# RTS5918 register map
Vendor: Realtek Semiconductor Corp.; Series: RTS5918 Series; File version: 1.00
CPU: ARMV8MML r0p0, little endian, MPU, FPU, VTOR, 3 interrupt priority bits, 8 SAU regions
Registers are 32-bit, read-write, reset 0x0 unless marked. A register's access mark holds for its fields unless they carry their own. Offsets are from the block's base; [hi:lo] are bit positions; {n}, {i} and the like mark numbered series; 'fields as' and 'values as' point back to an identical list.

## I3C0 — I3C Controller
Base 0x40003000
Same registers: I3C1 0x40004000
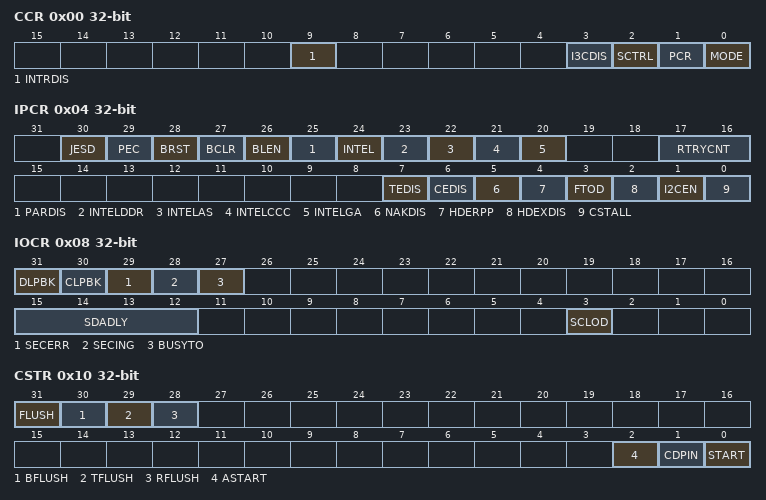
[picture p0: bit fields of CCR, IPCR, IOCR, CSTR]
0x00 CCR — CONFIGURATION CONTROL REGISTER
  [9] INTRDIS — Interrupt Disable
    0=ENABLE (Enable interrupt); 1=DISABLE (Disable interrupt)
  [3] I3CDIS — I3C Disable
    0=ENABLE (Enable I3C); 1=DISABLE (Disable I3C)
  [2] SCTRL — Secondary Control Mode
    0=DISABLE (Disable secondary control mode); 1=ENABLE (Enable secondary control mode)
  [1] PCR — Primary Control
    0=DISABLE (Not Primary Control); 1=ENABLE (Primary Control)
  [0] MODE — Mode Select
    0=CONTROLLER (I3C Controller); 1=TARGET (I3C Target)
0x04 IPCR — IXC PROTOCOL CONTROL REGISTER
  [30] JESD — JESD Spec. Enable
    0=DISABLE (Disable JESD); 1=ENABLE (Enable JESD)
  [29] PEC — PEC CRC Enable
    0=DISABLE (Disable PEC CRC); 1=ENABLE (Enable PEC CRC)
  [28] BRST — Bus Reset Enable
    0=DISABLE (Disable bus reset); 1=ENABLE (Enable bus reset)
  [27] BCLR — Bus Clear Enable
    0=DISABLE (Disable bus clear); 1=ENABLE (Enable bus clear)
  [26] BLEN — BL Enable
    0=DISABLE (Disable BL); 1=ENABLE (Enable BL)
  [25] PARDIS — Parity Disable
    0=ENABLE (Enable Parity); 1=DISABLE (Disable Parity)
  [24] INTEL — INTEL Spec. Enable
    0=DISABLE (Disable Intel spec.); 1=ENABLE (Enable Intel spec.)
  [23] INTELDDR — INTEL Spec. Extend DDR Enable
    0=DISABLE (Disable Intel Spec. extend DDR); 1=ENABLE (Enable Intel Spec. extend DDR)
  [22] INTELAS — INTEL Spec. Extend AS Enable
    0=DISABLE (Disable Intel Spec. extend AS); 1=ENABLE (Enable Intel Spec. extend AS)
  [21] INTELCCC — INTEL Spec. Extend CCC Enable
    0=DISABLE (Disable Intel Spec. extend CCC); 1=ENABLE (Enable Intel Spec. extend CCC)
  [20] INTELGA — INTEL Spec. Extend GA Enable
    0=DISABLE (Disable Intel Spec. extend GA); 1=ENABLE (Enable Intel Spec. extend GA)
  [17:16] RTRYCNT — Read Retry Count
  [7] TEDIS — TAGT Error Disable
    0=ENABLE (Enable target mode error); 1=DISABLE (Disable target mode error)
  [6] CEDIS — CTRL Error Disable
    0=ENABLE (Enable control mode error); 1=DISABLE (Disable control mode error)
  [5] NAKDIS — RX NACK Disable
    0=ENABLE (Enable RX NACK); 1=DISABLE (Disable RX NACK)
  [4] HDERPP — Header Address turn to PP Timing Enable
    0=DISBLE (Disable header addr. turn to PP timing); 1=ENABLE (Enable header addr. turn to PP timing)
  [3] FTOD — Force Timing = OD Enable
    0=DISBLE (Disable force timing); 1=ENABLE (Enable force timing)
  [2] HDEXDIS — HDR Exit Pattern Disable
    0=ENBLE (HDR exit pattern enable); 1=DISABLE (HDR exit pattern disable)
  [1] I2CEN — I2C Bus Enable
    0=DISBLE (I2C bus disable); 1=ENABLE (I2C bus enable)
  [0] CSTALL ro — SCL Stall Enable
0x08 IOCR — I/O CONFIGURATION CONTROL REGISTER
  [31] DLPBK — SDA LPBK Enable
    0=DISBLE (SDA LPBK disable); 1=ENABLE (SDA LPBK enable)
  [30] CLPBK — SCL LPBK Enable
    0=DISBLE (SCL LPBK disable); 1=ENABLE (SCL LPBK enable)
  [29] SECERR — Indicated for I3C SEC HP Flow Occured an Error
    0=NONE (Normal); 1=ERROR (I3C SEC HP flow Error)
  [28] SECING — Indicated for I3C SEC HP Flow Running
    0=NONE (Idle); 1=RUNNING (I3C SEC HP flow running)
  [27] BUSYTO — Turn to Idle when SCL/SDA hold for tIDLE
    0=NONE; 1=IDLE (Turn to idle)
  [15:12] SDADLY — SDA Deslay Count
  [3] SCLOD — Force SCL in Open-Drain Status
0x10 CSTR — CONTROL STRUCTURE REGISTER
  [31] FLUSH — Flush BYFM/TXDA/RXDA and Recovery IXC Status
  [30] BFLUSH — Flush BYFM FIFO
  [29] TFLUSH — Flush TXDA FIFO
  [28] RFLUSH — Flush RXDA/RCMD FIFO
  [2] ASTART — Control structure async mode 0 flow start
  [1] CDPIN — CD Pin start
  [0] START — Control structure flow start
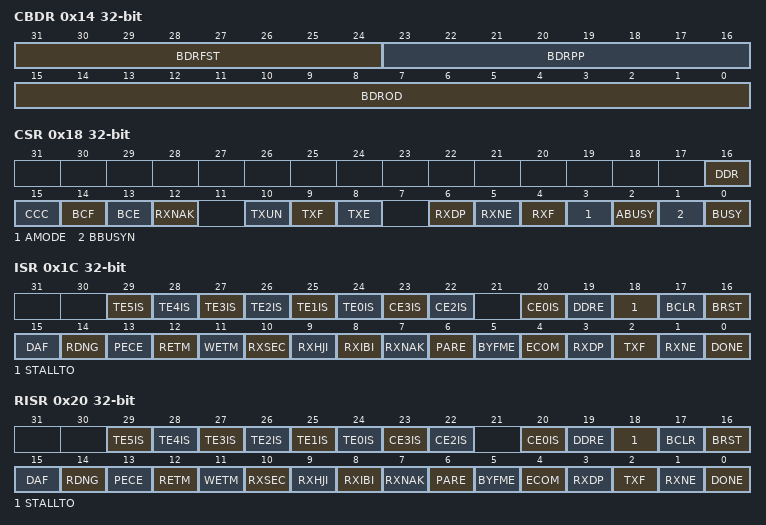
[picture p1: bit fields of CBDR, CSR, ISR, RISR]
0x14 CBDR — SCL BAUD RATE REGISTER
  [31:24] BDRFST — Baud rate for the first header address
  [23:16] BDRPP — Baud rate for PP
  [15:0] BDROD — Baud rate for OD
0x18 CSR — CURRENT STATUS REGISTER
  [16] DDR ro — HDR-DDR MODE
  [15] CCC ro — RECEIVE A CCC CMD IN TARGET MODE
  [14] BCF ro — BYFM CMD FIFO FULL
  [13] BCE ro — BYFM CMD FIFO EMPTY
  [12] RXNAK ro — RECIEVED NACK
  [10] TXUN ro — TXDA UBDERFLOW
  [9] TXF ro — TXDA FULL
  [8] TXE ro — TXDA EMPTY
  [6] RXDP ro — RX DATA DROP
  [5] RXNE ro — RX DATA NOT EMPTY
  [4] RXF ro — RX DATA FULL
  [3] AMODE — IN ASYNC MODE 0
  [2] ABUSY ro — ASYNC MODE 0 BUSY
  [1] BBUSYN ro — BUS IDLE
  [0] BUSY ro
0x1C ISR ro — INTERRUPT STATUS REGISTER
  [29] TE5IS — SDR target error type 5
  [n+24] TE{n}IS (n=0..4) — SDR Target Error Type {n}
  [23] CE3IS — SDR Controller Error Type 3
  [22] CE2IS — SDR Controller Error Type 2
  [20] CE0IS — SDR Controller Error Type 0
  [19] DDRE — DDR Preamble / Parity / CRC Error
  [18] STALLTO — SCL Stall Timeout in CTRL Mode / BUS Buy Timeout in TAGT Mode
  [17] BCLR — Bus Clear
  [16] BRST — Bus Reset
  [15] DAF — SDA Arbitration Fail
  [14] RDNG — Read RXDA word unaligned
  [13] PECE — PEC CRC Error
  [12] RETM — Read Early Terminate Occur
  [11] WETM — Write Early Terminate Occur
  [10] RXSEC — Receieve Role REQ / Receieve CCC GETACCCR
  [9] RXHJI — Receieve Hot Join REQ
  [8] RXIBI — Receieve IBI REQ
  [7] RXNAK — Receieve NACK
  [6] PARE — PAR-bit Error
  [5] BYFME — BYFME Error
  [4] ECOM — Early Complete Transaction
  [3] RXDP — RX Data Drop Occur
  [2] TXF — TXDA Full
  [1] RXNE — RXDA Not Empty
  [0] DONE — I3C/I2C Transation is Done
0x20 RISR — INTERRUPT RAW STATUS REGISTER
  fields as ISR
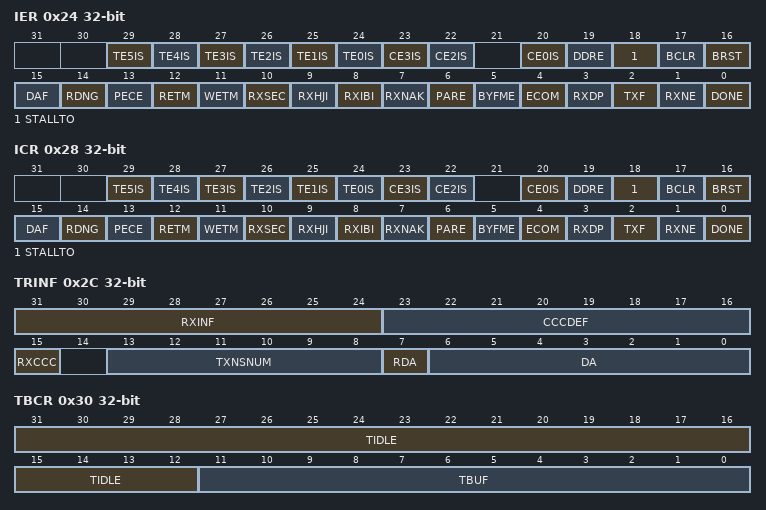
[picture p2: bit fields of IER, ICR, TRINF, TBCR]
0x24 IER — INTERRUPT ENABLE CONTROL REGISTER
  fields as ISR
0x28 ICR — INTERRUPT CLEAR REGISTER
  fields as ISR
0x2C TRINF — TRANSACTION INFORMATION REGISTER
  [31:24] RXINF ro — CCC_CMD for TAGT / IBI_MDB for CTRL
  [23:16] CCCDEF ro — CCC.DEFINING for TAGT
  [15] RXCCC ro — REVEIVE A CCC CMD for TAGT
  [13:8] TXNSNUM ro — Transacation for ROLE CTRL
  [7] RDA ro — HDR-DDR REQ for TAGT / IBI or HJ or SEC REQ for CTRL
  [6:0] DA ro — HDR-DDR CMD Code / IBI or HJ or SEC REQ's DA for CTRL
0x30 TBCR — BUS TIMING REGISTER
  [31:12] TIDLE — Bus Idle Timing (tIDLE) Count
  [11:0] TBUF — Bus Free Timing (tBUF) Count
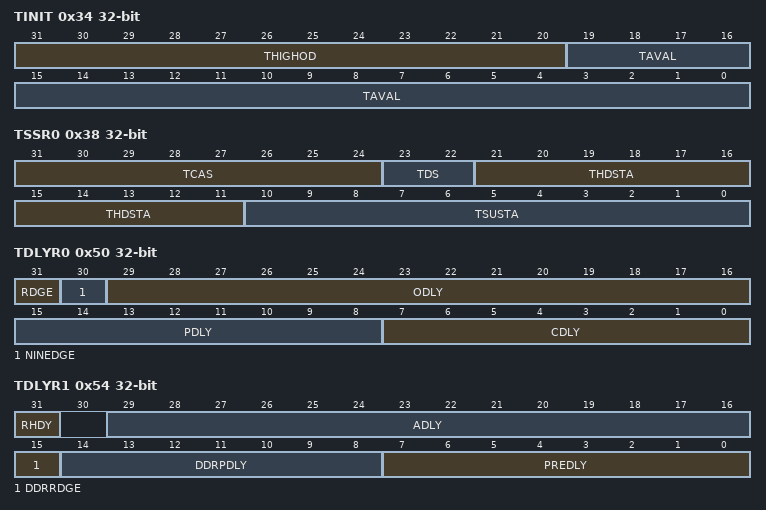
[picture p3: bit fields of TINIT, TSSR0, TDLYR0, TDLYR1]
0x34 TINIT — INITIAL TIMING REGISTER
  [31:20] THIGHOD — SCL High Count for OD Timing
  [19:0] TAVAL — Bus Available Timing (tAVAL) Count
0x38 TSSR0 — TIMING START REGISTER 0
  [31:24] TCAS — tCAS Timing Count
  [23:22] TDS — tDS Timing Count
  [21:11] THDSTA — tHD_STA Timing Count
  [10:0] TSUSTA — tSU_STA Timing Count
0x3C TSSR1 — TIMING STOP REGISTER 1
  [11:0] TSUSTO — tSU_STO Timing Count
0x50 TDLYR0 — TIMING DELAY REGISTER 0
  [31] RDGE — SDR RXDA Capture Edge when cr_9dge Set
  [30] NINEDGE — SDR RXDA Capture Edge According to CR_RDGE
  [29:16] ODLY — SDR Receieve Delay in OD mode
  [15:8] PDLY — SDR Receieve Delay in PP mode
  [7:0] CDLY — SCL Receieve Delay in PP mode
0x54 TDLYR1 — TIMING DELAY REGISTER 1
  [31] RHDY — SDR RXDA Capture High Edge Delay Enable
  [29:16] ADLY — SDR RX Delay for 9th Header/Data phase in OD mode
  [15] DDRRDGE — Capture Point in DDR mode
  [14:8] DDRPDLY — SDR Receieve Delay in DDR mode
  [7:0] PREDLY — SCL Low Delay Time before Preamble Phase in DDR Mode
0x58 TRST — TIMING BUS RESET REGISTER
  [19:0] BRST — BUS Reset Timing
0x70 TXFL ro — TXDA FIFO Level
0x74 RXFL ro — RXDA FIFO Level
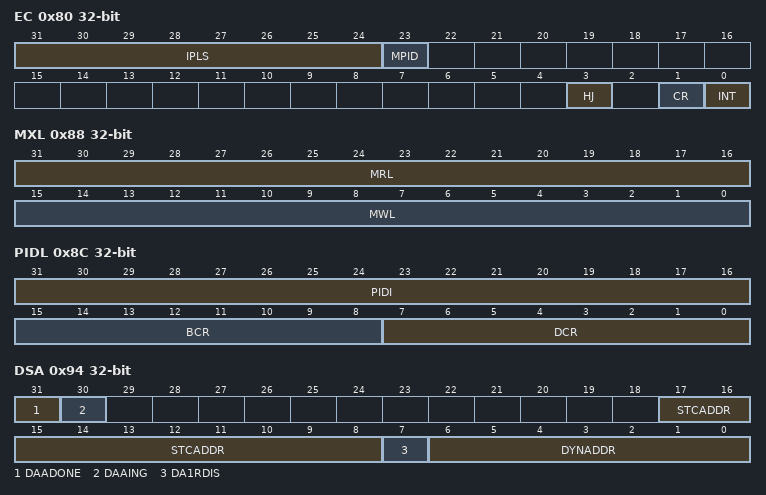
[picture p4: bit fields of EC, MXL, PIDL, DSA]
0x80 EC — I3C TARGET EVENT BYTE REGISTER
  [31:24] IPLS — IBI PAYLOAD SIZE
  [23] MPID — I3C ID From CR_PIDH ADN CR_PIDL
  [3] HJ — HOT JOIN
  [1] CR — CONTROL REGISTER BIT
  [0] INT — INTERRUPT BIT
0x84 AS — ACTIVITY STATE REGISTER
  [31:24] AS — IBI PAYLOAD SIZE
    0=1 us; 1=100 us; 2=2 ms; 3=50 ms
0x88 MXL — MAX R/W LENGTH REGISTER
  [31:16] MRL — Max Read Length for SETMRL/GETMRL
  [15:0] MWL — Max WRITE Length for SETMWL/GETMWL
0x8C PIDL
  [31:16] PIDI — I3C.PID[15:0]
  [15:8] BCR — I3C.BCR
  [7:0] DCR — I3C.DCR
0x90 PIDH
0x94 DSA — DYNAMIC/STATIC ADDRESS REGISTER
  [31] DAADONE ro — I3C Dynamic Address Assign Flow is Done
  [30] DAAING ro — I3C Dynamic Address Assign Flow is Running
  [17:8] STCADDR — Static Address
  [7] DA1RDIS — SETDASA Format 2
  [6:0] DYNADDR ro — DYNAMIC ADDRESS
0x98 CCCST — DEVICE STATUS (GETSTATUS) REGISTER
  [15:0] STATUS — CCC: GETSTATUS
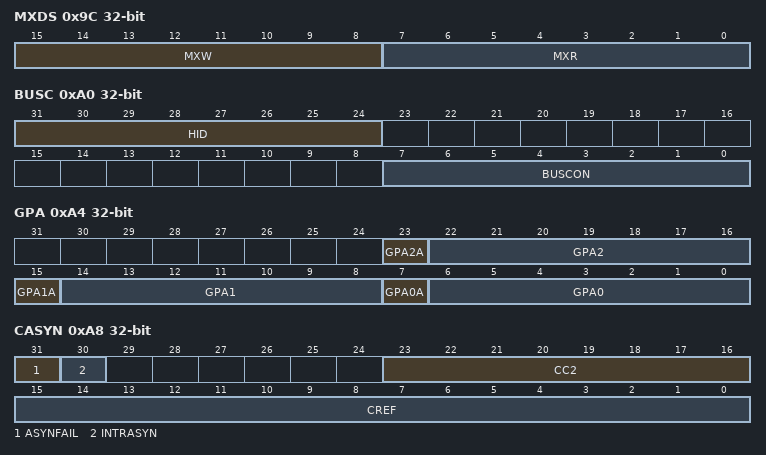
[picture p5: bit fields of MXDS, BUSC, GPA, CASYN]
0x9C MXDS — MAX DATA SPEED REGISTER
  [15:8] MXW — Transaction Value by CCC: GETMXDS
  [7:0] MXR — Reply Value by CCC: GETMXDSS
0xA0 BUSC — BUS CONTEXT REGISTER
  [31:24] HID ro — CCC.SETHID
  [7:0] BUSCON ro — Bus Context
0xA4 GPA — GROUP ADDRESS REGISTER
  [23] GPA2A ro — Group Address 2 Assigned
  [22:16] GPA2 ro — Group Address 2 for TAGT Mode
  [15] GPA1A ro — Group Address 1 Assigned
  [14:8] GPA1 ro — Group Address 1 for TAGT Mode
  [7] GPA0A ro — Group Address 0 Assigned
  [6:0] GPA0 ro — Group Address 0 for TAGT Mode
0xA8 CASYN — CONTROLLER ASYN TIMING REGISTER
  [31] ASYNFAIL ro — C_REF/C2 Counter Overflow
  [30] INTRASYN ro — ASYN IBI Finished
  [23:16] CC2 ro — First SCL Positive Edge after IBI_ACK to First SCL Positive Edge after T-Bit of IBI's MDB
  [15:0] CREF ro — IBI to First SCL Positive after IBI_ACK
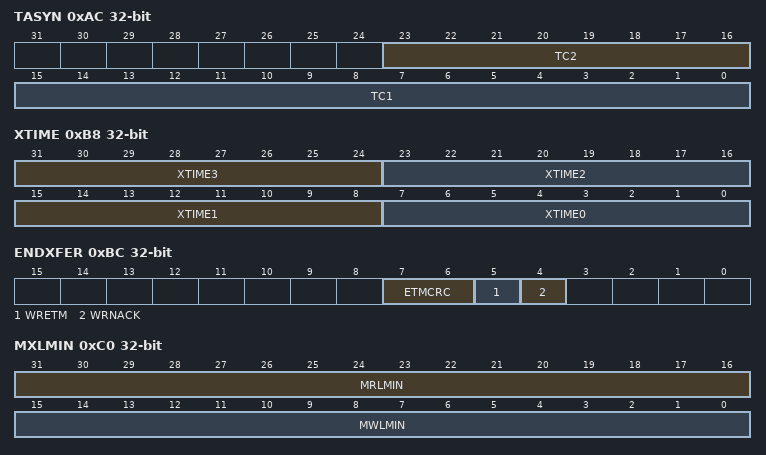
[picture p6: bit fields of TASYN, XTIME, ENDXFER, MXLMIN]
0xAC TASYN — TARGET ASYN TIMING REGISTER
  [23:16] TC2 ro — First SCL Positive Edge after IBI_ACK to First SCL Positive Edge after T-Bit of IBI's MDB
  [15:0] TC1 ro — IBI to First SCL Positive after IBI_ACK
0xB0 DCTRL ro — DEVCTRL REGISTER
0xB4 DCAP — DEVCAP REGISTER
  [15:0] DEVCAP ro — Data Payload for CCC.DEVCAP
0xB8 XTIME — EXCAHNGE TIMING SUPPORT INFORMATION REGISTER
  [31:24] XTIME3 — Data Byte (Supported Modes) for CCC.GETXTIME
  [23:16] XTIME2 — Data Byte (State) for CCC.GETXTIME
  [15:8] XTIME1 — Data Byte (Frequency) for CCC.GETXTIME
  [7:0] XTIME0 — Data Byte (Inaccuracy) for CCC.GETXTIME
0xBC ENDXFER — ENDXFER EARLY TERMINATION PARAMETERS REGISTER
  [7:6] ETMCRC — Data Byte (Supported Modes) for CCC.GETXTIME
    0=NOCRC (No CRC follows early termination request); 1=CRC (CRC follows early termination request)
  [5] WRETM — Enable HDR Write Early Termination Request
    0=ENABLE (Enable HDR Write Early Termination Request); 1=DISABLE (Disable HDR Write Early Termination Request)
  [4] WRNACK — Enable ACK-NACK Capability for Write Command
    0=ENABLE (Enable ACK-NACK Capability for Write Command); 1=DISABLE (Disable ACK-NACK Capability for Write Command)
0xC0 MXLMIN — MRL/MWL DEFINED MINIMUM VALUE REGISTER
  [31:16] MRLMIN — MRL Defined Minimum Value
  [15:0] MWLMIN — MWL Defined Minimum Value
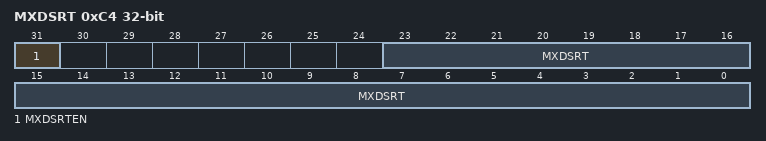
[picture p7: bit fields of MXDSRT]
0xC4 MXDSRT — MAX DATA READTURN REGISTER
  [31] MXDSRTEN — Max Data Read turn Enable
    0=DISABLE (No MAX read turn bytes); 1=ENABLE (IP will provide 3-bytes read turn for CCC.GETMXDS)
  [23:0] MXDSRT — 3-BYTES MAX READ TURN
0xC8 RSTACT
0xE0 MEMDR — DATA REGISTER 0
0xEC RWCMD ro — VENDOR DIRECT CCC FOR ACCESS TO CONTROL REGISTERS
0xFC MDB — MDB LIST REGISTERS
{0x100+4i} CFR[{i}] (i=0..15) — CONTROL BYFM FIFO REGISTERS
0x140 TDFR — TXDA FIFO REGISTERS
0x1C0 RCFR ro — RX COMMAND REGISTERS
